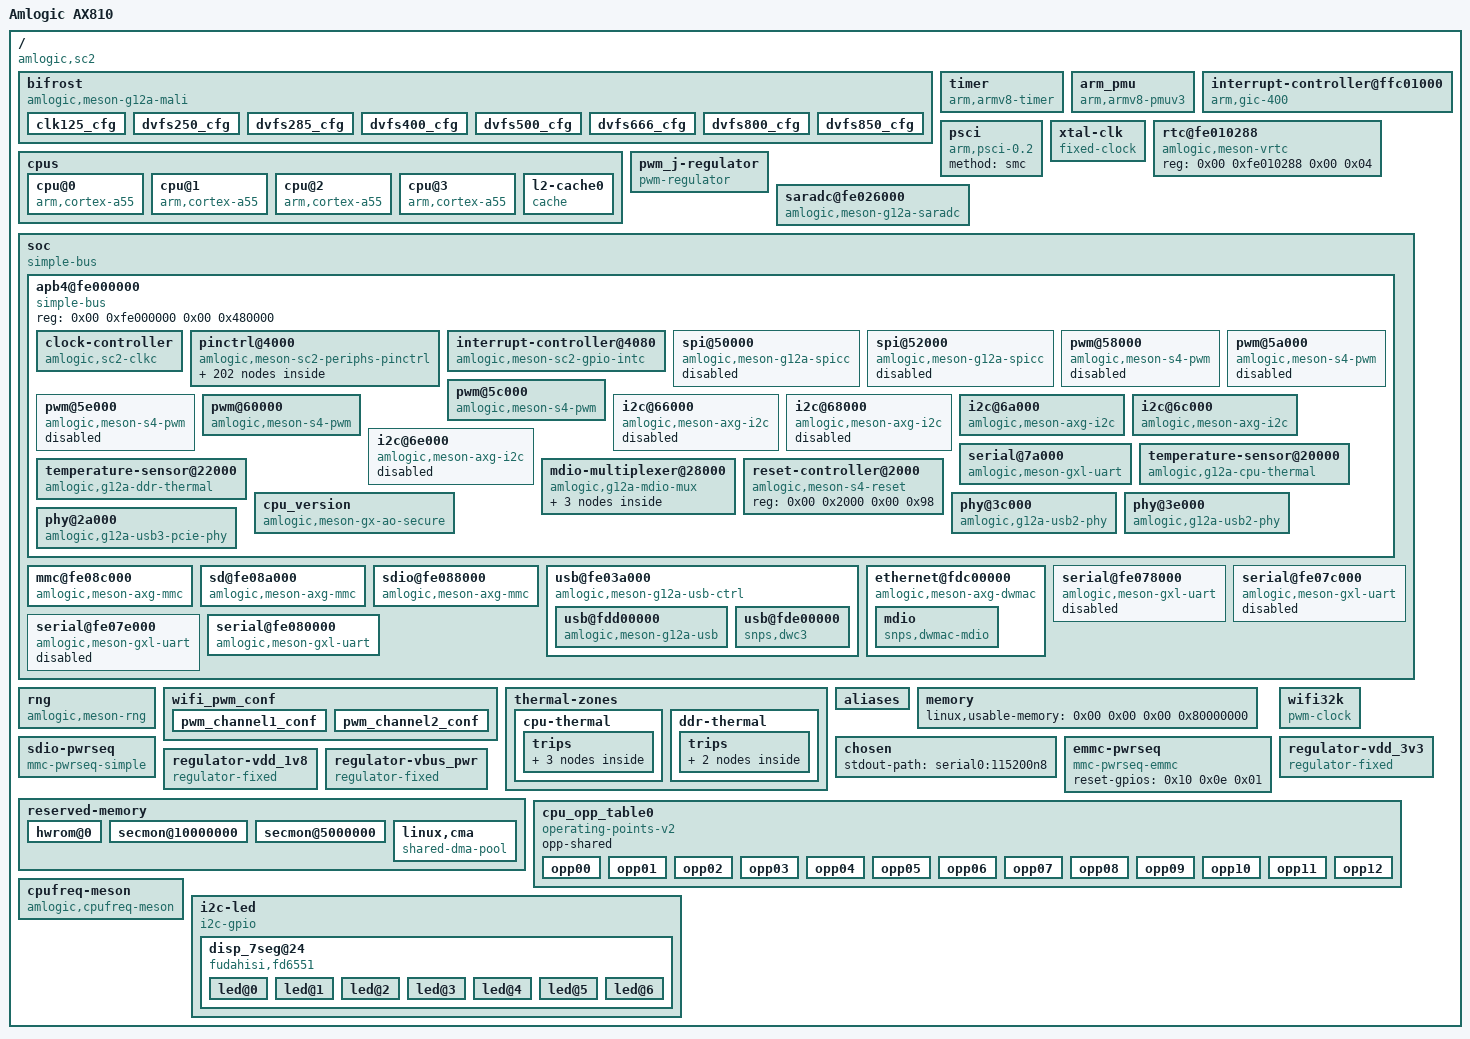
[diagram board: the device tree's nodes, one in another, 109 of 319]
/dts-v1/;
 
/ {
	model = "Amlogic AX810";
	compatible = "amlogic,sc2";
	interrupt-parent = <0x01>;
	#address-cells = <0x02>;
	#size-cells = <0x02>;
 
	bifrost {
		compatible = "amlogic,meson-g12a-mali";
		#cooling-cells = <0x02>;
		reg = <0x00 0xfe400000 0x00 0x4000 0x00 0xfe002000 0x00 0x1000 0x00 0xff800000 0x00 0x1000 0x00 0xff63c000 0x00 0x1000 0x00 0xfe002000 0x00 0x1000>;
		interrupt-parent = <0x01>;
		interrupts = <0x00 0x90 0x04 0x00 0x91 0x04 0x00 0x92 0x04>;
		interrupt-names = "gpu\0mmu\0job";
		tbl = <0x02 0x03 0x04 0x05 0x06 0x06>;
		resets = <0x07 0x22 0x07 0x21>;
		clk_cntl_reg = <0x57>;
		clocks = <0x08 0x93>;
		clock-names = "gpu_mux";
		assigned-clocks = <0x08 0x8d 0x08 0x8f 0x08 0x93>;
		assigned-clock-parents = <0x08 0x0f 0x00 0x08 0x8f>;
		assigned-clock-rates = <0x00 0x2faf0800 0x00>;
		phandle = <0x2d>;
 
		clk125_cfg {
			clk_freq = <0x7735940>;
			clk_parent = "fclk_div4";
			clkp_freq = <0x1dcd6500>;
			clk_reg = <0xa03>;
			voltage = <0x47e>;
			keep_count = <0x05>;
			threshold = <0x1e 0x78>;
			phandle = <0x2e>;
		};
 
		dvfs250_cfg {
			clk_freq = <0xee6b280>;
			clk_parent = "fclk_div4";
			clkp_freq = <0x1dcd6500>;
			clk_reg = <0xa01>;
			voltage = <0x47e>;
			keep_count = <0x05>;
			threshold = <0x00 0x4c>;
			phandle = <0x2f>;
		};
 
		dvfs285_cfg {
			clk_freq = <0x1107a76d>;
			clk_parent = "fclk_div7";
			clkp_freq = <0x1107a76d>;
			clk_reg = <0xe00>;
			voltage = <0x47e>;
			keep_count = <0x05>;
			threshold = <0x00 0x4c>;
			phandle = <0x02>;
		};
 
		dvfs400_cfg {
			clk_freq = <0x17d78400>;
			clk_parent = "fclk_div5";
			clkp_freq = <0x17d78400>;
			clk_reg = <0xc00>;
			voltage = <0x47e>;
			keep_count = <0x05>;
			threshold = <0x50 0x78>;
			phandle = <0x03>;
		};
 
		dvfs500_cfg {
			clk_freq = <0x1dcd6500>;
			clk_parent = "fclk_div4";
			clkp_freq = <0x1dcd6500>;
			clk_reg = <0xa00>;
			voltage = <0x47e>;
			keep_count = <0x05>;
			threshold = <0x50 0x78>;
			phandle = <0x04>;
		};
 
		dvfs666_cfg {
			clk_freq = <0x27bc86aa>;
			clk_parent = "fclk_div3";
			clkp_freq = <0x27bc86aa>;
			clk_reg = <0x800>;
			voltage = <0x47e>;
			keep_count = <0x05>;
			threshold = <0x50 0x78>;
			phandle = <0x05>;
		};
 
		dvfs800_cfg {
			clk_freq = <0x2faf0800>;
			clk_parent = "fclk_div2p5";
			clkp_freq = <0x2faf0800>;
			clk_reg = <0x600>;
			voltage = <0x47e>;
			keep_count = <0x05>;
			threshold = <0x50 0xff>;
			phandle = <0x30>;
		};
 
		dvfs850_cfg {
			clk_freq = <0x326cef80>;
			clk_parent = "gp0_pll";
			clkp_freq = <0x326cef80>;
			clk_reg = <0x200>;
			voltage = <0x47e>;
			keep_count = <0x05>;
			threshold = <0x50 0xff>;
			phandle = <0x06>;
		};
	};
 
	cpus {
		#address-cells = <0x02>;
		#size-cells = <0x00>;
		phandle = <0x31>;
 
		cpu@0 {
			device_type = "cpu";
			compatible = "arm,cortex-a55";
			reg = <0x00 0x00>;
			enable-method = "psci";
			next-level-cache = <0x09>;
			dynamic-power-coefficient = <0xe6>;
			#cooling-cells = <0x02>;
			clocks = <0x08 0x1b 0x08 0x1a 0x08 0x03 0x08 0x24 0x08 0x23>;
			clock-names = "core_clk\0low_freq_clk_parent\0high_freq_clk_parent\0dsu_clk\0dsu_pre_parent";
			operating-points-v2 = <0x0a>;
			cpu-supply = <0x0b>;
			voltage-tolerance = <0x00>;
			clock-latency = <0xc350>;
			phandle = <0x32>;
		};
 
		cpu@1 {
			device_type = "cpu";
			compatible = "arm,cortex-a55";
			reg = <0x00 0x01>;
			enable-method = "psci";
			next-level-cache = <0x09>;
			dynamic-power-coefficient = <0xe6>;
			#cooling-cells = <0x02>;
			clocks = <0x08 0x1b 0x08 0x1a 0x08 0x03 0x08 0x24 0x08 0x23>;
			clock-names = "core_clk\0low_freq_clk_parent\0high_freq_clk_parent\0dsu_clk\0dsu_pre_parent";
			operating-points-v2 = <0x0a>;
			cpu-supply = <0x0b>;
			voltage-tolerance = <0x00>;
			clock-latency = <0xc350>;
			phandle = <0x33>;
		};
 
		cpu@2 {
			device_type = "cpu";
			compatible = "arm,cortex-a55";
			reg = <0x00 0x02>;
			enable-method = "psci";
			next-level-cache = <0x09>;
			dynamic-power-coefficient = <0xe6>;
			#cooling-cells = <0x02>;
			clocks = <0x08 0x1b 0x08 0x1a 0x08 0x03 0x08 0x24 0x08 0x23>;
			clock-names = "core_clk\0low_freq_clk_parent\0high_freq_clk_parent\0dsu_clk\0dsu_pre_parent";
			operating-points-v2 = <0x0a>;
			cpu-supply = <0x0b>;
			voltage-tolerance = <0x00>;
			clock-latency = <0xc350>;
			phandle = <0x34>;
		};
 
		cpu@3 {
			device_type = "cpu";
			compatible = "arm,cortex-a55";
			reg = <0x00 0x03>;
			enable-method = "psci";
			next-level-cache = <0x09>;
			dynamic-power-coefficient = <0xe6>;
			#cooling-cells = <0x02>;
			clocks = <0x08 0x1b 0x08 0x1a 0x08 0x03 0x08 0x24 0x08 0x23>;
			clock-names = "core_clk\0low_freq_clk_parent\0high_freq_clk_parent\0dsu_clk\0dsu_pre_parent";
			operating-points-v2 = <0x0a>;
			cpu-supply = <0x0b>;
			voltage-tolerance = <0x00>;
			clock-latency = <0xc350>;
			phandle = <0x35>;
		};
 
		l2-cache0 {
			compatible = "cache";
			phandle = <0x09>;
		};
	};
 
	timer {
		compatible = "arm,armv8-timer";
		interrupts = <0x01 0x0d 0xff08 0x01 0x0e 0xff08 0x01 0x0b 0xff08 0x01 0x0a 0xff08>;
	};
 
	arm_pmu {
		compatible = "arm,armv8-pmuv3";
		private-interrupts;
		interrupts = <0x00 0xeb 0x04 0x00 0xec 0x04 0x00 0xed 0x04 0x00 0xee 0x04>;
		reg = <0x00 0xff634680 0x00 0x04>;
		cpumasks = <0x0f>;
		relax-timer-ns = <0x989680>;
		max-wait-cnt = <0x2710>;
	};
 
	interrupt-controller@ffc01000 {
		compatible = "arm,gic-400";
		#interrupt-cells = <0x03>;
		#address-cells = <0x00>;
		interrupt-controller;
		reg = <0x00 0xfff01000 0x00 0x1000 0x00 0xfff02000 0x00 0x2000 0x00 0xfff04000 0x00 0x2000 0x00 0xfff06000 0x00 0x2000>;
		interrupts = <0x01 0x09 0xff04>;
		phandle = <0x01>;
	};
 
	psci {
		compatible = "arm,psci-0.2";
		method = "smc";
	};
 
	xtal-clk {
		compatible = "fixed-clock";
		clock-frequency = <0x16e3600>;
		clock-output-names = "xtal";
		#clock-cells = <0x00>;
		phandle = <0x0d>;
	};
 
	rtc@fe010288 {
		compatible = "amlogic,meson-vrtc";
		reg = <0x00 0xfe010288 0x00 0x04>;
		status = "okay";
		phandle = <0x36>;
	};
 
	pwm_j-regulator {
		compatible = "pwm-regulator";
		pwms = <0x0c 0x01 0x5dc 0x00>;
		regulator-name = "vddcpu0";
		regulator-min-microvolt = <0xa8368>;
		regulator-max-microvolt = <0x1001a8>;
		regulator-always-on;
		max-duty-cycle = <0x5dc>;
		voltage-table = <0x1001a8 0x00 0xfda98 0x03 0xfb388 0x06 0xf8c78 0x09 0xf6568 0x0c 0xf3e58 0x0e 0xf1748 0x11 0xef038 0x14 0xec928 0x17 0xea218 0x1a 0xe7b08 0x1d 0xe53f8 0x1f 0xe2ce8 0x22 0xe05d8 0x25 0xddec8 0x28 0xdb7b8 0x2b 0xd90a8 0x2d 0xd6998 0x30 0xd4288 0x33 0xd1b78 0x36 0xcf468 0x38 0xccd58 0x3b 0xca648 0x3e 0xc7f38 0x41 0xc5828 0x44 0xc3118 0x46 0xc0a08 0x49 0xbe2f8 0x4c 0xbbbe8 0x4f 0xb94d8 0x51 0xb6dc8 0x54 0xb46b8 0x57 0xb1fa8 0x59 0xaf898 0x5c 0xad188 0x5f 0xaaa78 0x62 0xa8368 0x64>;
		status = "okay";
		phandle = <0x0b>;
	};
 
	saradc@fe026000 {
		compatible = "amlogic,meson-g12a-saradc\0amlogic,meson-saradc";
		status = "okay";
		#io-channel-cells = <0x01>;
		clocks = <0x0d 0x08 0x138 0x08 0x106 0x08 0x104>;
		clock-names = "clkin\0core\0adc_clk\0adc_sel";
		interrupts = <0x00 0xb5 0x01>;
		reg = <0x00 0xfe026000 0x00 0x48>;
		phandle = <0x37>;
	};
 
	soc {
		compatible = "simple-bus";
		#address-cells = <0x02>;
		#size-cells = <0x02>;
		ranges;
 
		apb4@fe000000 {
			compatible = "simple-bus";
			reg = <0x00 0xfe000000 0x00 0x480000>;
			#address-cells = <0x02>;
			#size-cells = <0x02>;
			ranges = <0x00 0x00 0x00 0xfe000000 0x00 0x480000>;
			phandle = <0x38>;
 
			clock-controller {
				compatible = "amlogic,sc2-clkc";
				#clock-cells = <0x01>;
				reg = <0x00 0x00 0x00 0x49c 0x00 0x8000 0x00 0x2e8 0x00 0xe140 0x00 0x24>;
				reg-names = "basic\0pll\0cpu_clk";
				clocks = <0x0d>;
				clock-names = "xtal";
				status = "okay";
				phandle = <0x08>;
			};
 
			pinctrl@4000 {
				compatible = "amlogic,meson-sc2-periphs-pinctrl";
				#address-cells = <0x02>;
				#size-cells = <0x02>;
				ranges;
				phandle = <0x0e>;
 
				bank@4000 {
					reg = <0x00 0x4000 0x00 0x4c 0x00 0x40c0 0x00 0x220>;
					reg-names = "mux\0gpio";
					gpio-controller;
					#gpio-cells = <0x02>;
					gpio-ranges = <0x0e 0x00 0x00 0x57>;
					phandle = <0x10>;
				};
 
				i2c0_pins1 {
					phandle = <0x39>;
 
					mux {
						groups = "i2c0_sda_c\0i2c0_scl_c";
						function = "i2c0";
						bias-disable;
					};
				};
 
				i2c0_pins2 {
					phandle = <0x3a>;
 
					mux {
						groups = "i2c0_sda_h\0i2c0_scl_h";
						function = "i2c0";
						bias-disable;
					};
				};
 
				i2c0_pins3 {
					phandle = <0x3b>;
 
					mux {
						groups = "i2c0_sda_z0\0i2c0_scl_z1";
						function = "i2c0";
						bias-disable;
					};
				};
 
				i2c0_pins4 {
					phandle = <0x3c>;
 
					mux {
						groups = "i2c0_sda_z7\0i2c0_scl_z8";
						function = "i2c0";
						bias-disable;
					};
				};
 
				i2c1_pins1 {
					phandle = <0x3d>;
 
					mux {
						groups = "i2c1_sda_z\0i2c1_scl_z";
						function = "i2c1";
						bias-disable;
					};
				};
 
				i2c1_pins2 {
					phandle = <0x3e>;
 
					mux {
						groups = "i2c1_sda_x\0i2c1_scl_x";
						function = "i2c1";
						bias-disable;
					};
				};
 
				i2c1_pins3 {
					phandle = <0x3f>;
 
					mux {
						groups = "i2c1_sda_h2\0i2c1_scl_h3";
						function = "i2c1";
						bias-disable;
					};
				};
 
				i2c1_pins4 {
					phandle = <0x40>;
 
					mux {
						groups = "i2c1_sda_h6\0i2c1_scl_h7";
						function = "i2c1";
						bias-disable;
					};
				};
 
				i2c2_pins1 {
					phandle = <0x41>;
 
					mux {
						groups = "i2c2_sda_x\0i2c2_scl_x";
						function = "i2c2";
						bias-disable;
					};
				};
 
				i2c2_pins2 {
					phandle = <0x42>;
 
					mux {
						groups = "i2c2_sda_z10\0i2c2_scl_z11";
						function = "i2c2";
						bias-disable;
					};
				};
 
				i2c2_pins3 {
					phandle = <0x13>;
 
					mux {
						groups = "i2c2_sda_z14\0i2c2_scl_z15";
						function = "i2c2";
						bias-disable;
					};
				};
 
				i2c3_pins1 {
					phandle = <0x43>;
 
					mux {
						groups = "i2c3_sda_h\0i2c3_scl_h";
						function = "i2c3";
						bias-disable;
					};
				};
 
				i2c3_pins2 {
					phandle = <0x14>;
 
					mux {
						groups = "i2c3_sda_a\0i2c3_scl_a";
						function = "i2c3";
						bias-disable;
					};
				};
 
				i2c4_pins1 {
					phandle = <0x44>;
 
					mux {
						groups = "i2c4_sda_d\0i2c4_scl_d";
						function = "i2c4";
						bias-disable;
					};
				};
 
				i2c4_pins2 {
					phandle = <0x45>;
 
					mux {
						groups = "i2c4_sda_e\0i2c4_scl_e";
						function = "i2c4";
						bias-disable;
					};
				};
 
				a_uart1 {
					phandle = <0x25>;
 
					mux {
						groups = "uart_a_tx_d2\0uart_a_rx_d3";
						function = "uart_a";
					};
				};
 
				a_uart2 {
					phandle = <0x46>;
 
					mux {
						groups = "uart_a_tx_d8\0uart_a_rx_d9";
						function = "uart_a";
					};
				};
 
				c_uart {
					phandle = <0x26>;
 
					mux {
						groups = "uart_c_tx\0uart_c_rx";
						bias-pull-up;
						output-high;
						function = "uart_c";
					};
				};
 
				d_uart1 {
					phandle = <0x27>;
 
					mux {
						groups = "uart_d_tx_x6\0uart_d_rx_x7";
						function = "uart_d";
					};
				};
 
				d_uart2 {
					phandle = <0x47>;
 
					mux {
						groups = "uart_d_tx_x10\0uart_d_rx_x11";
						function = "uart_d";
					};
				};
 
				e_uart {
					phandle = <0x28>;
 
					mux {
						groups = "uart_e_tx\0uart_e_rx\0uart_e_cts\0uart_e_rts";
						bias-pull-up;
						output-high;
						function = "uart_e";
					};
				};
 
				emmc {
					phandle = <0x16>;
 
					mux-0 {
						groups = "emmc_nand_d0\0emmc_nand_d1\0emmc_nand_d2\0emmc_nand_d3\0emmc_nand_d4\0emmc_nand_d5\0emmc_nand_d6\0emmc_nand_d7\0emmc_cmd";
						function = "emmc";
						bias-pull-up;
					};
 
					mux-1 {
						groups = "emmc_clk";
						function = "emmc";
						bias-disable;
					};
				};
 
				emmc-ds {
					phandle = <0x17>;
 
					mux {
						groups = "emmc_nand_dqs";
						function = "emmc";
						bias-pull-down;
					};
				};
 
				emmc_clk_gate {
					phandle = <0x18>;
 
					mux {
						groups = "GPIOB_8";
						function = "gpio_periphs";
						bias-pull-down;
					};
				};
 
				all_nand_pins {
					phandle = <0x48>;
 
					mux {
						groups = "emmc_nand_d0\0emmc_nand_d1\0emmc_nand_d2\0emmc_nand_d3\0emmc_nand_d4\0emmc_nand_d5\0emmc_nand_d6\0emmc_nand_d7\0nand_ce0\0nand_ale\0nand_cle\0nand_wen_clk\0nand_ren_wr";
						function = "nand";
						input-enable;
					};
				};
 
				nand_cs {
					phandle = <0x49>;
 
					mux {
						groups = "nand_ce0";
						function = "nand";
					};
				};
 
				sd_to_ao_uart_clr_pins {
					phandle = <0x4a>;
 
					mux {
						groups = "GPIOD_0\0GPIOD_1";
						function = "gpio_periphs";
					};
				};
 
				sdcard_pins {
					phandle = <0x1c>;
 
					mux-0 {
						groups = "sdcard_d0_c\0sdcard_d1_c\0sdcard_d2_c\0sdcard_d3_c\0sdcard_cmd_c";
						function = "sdcard";
						bias-pull-up;
					};
 
					mux-1 {
						groups = "sdcard_clk_c";
						function = "sdcard";
						bias-pull-up;
					};
				};
 
				sdio_clk_gate_pins {
					phandle = <0x1d>;
 
					mux {
						groups = "sdcard_clk_c";
						function = "sdcard";
						bias-pull-down;
					};
				};
 
				sdio {
					phandle = <0x1e>;
 
					mux-0 {
						groups = "sdio_d0_x\0sdio_d1_x\0sdio_d2_x\0sdio_d3_x\0sdio_cmd_x";
						function = "sdio";
						bias-pull-up;
					};
 
					mux-1 {
						groups = "sdio_clk_x";
						function = "sdio";
						bias-disable;
					};
				};
 
				sdio_clk_gate {
					phandle = <0x1f>;
 
					mux {
						groups = "GPIOX_4";
						function = "gpio_periphs";
						bias-pull-down;
					};
				};
 
				hdmitx_hpd {
					phandle = <0x4b>;
 
					mux {
						groups = "hdmitx_hpd_in";
						function = "hdmitx";
						bias-disable;
					};
				};
 
				hdmitx_hpd_gpio {
					phandle = <0x4c>;
 
					mux {
						groups = "GPIOH_1";
						function = "gpio_periphs";
						bias-disable;
					};
				};
 
				hdmitx_ddc {
					phandle = <0x4d>;
 
					mux {
						groups = "hdmitx_sda\0hdmitx_sck";
						function = "hdmitx";
						bias-disable;
					};
				};
 
				ee_ceca {
					phandle = <0x4e>;
 
					mux {
						groups = "cec_a_h";
						function = "cec_a";
					};
				};
 
				ee_cecb {
					phandle = <0x4f>;
 
					mux {
						groups = "cec_b_h";
						function = "cec_b";
					};
				};
 
				jtag_a_pin {
					phandle = <0x50>;
 
					mux {
						groups = "jtag_1_tdi\0jtag_1_tdo\0jtag_1_clk\0jtag_1_tms";
						function = "jtag_1";
					};
				};
 
				jtag_b_pin {
					phandle = <0x51>;
 
					mux {
						groups = "jtag_2_tdi\0jtag_2_tdo\0jtag_2_clk\0jtag_2_tms";
						function = "jtag_2";
					};
				};
 
				pwm_a_pins1 {
					phandle = <0x52>;
 
					mux {
						groups = "pwm_a_e";
						function = "pwm_a";
					};
				};
 
				pwm_a_pins2 {
					phandle = <0x53>;
 
					mux {
						groups = "pwm_a_x";
						function = "pwm_a";
					};
				};
 
				pwm_b_pins1 {
					phandle = <0x54>;
 
					mux {
						groups = "pwm_b_h";
						function = "pwm_b";
					};
				};
 
				pwm_b_pins2 {
					phandle = <0x55>;
 
					mux {
						groups = "pwm_b_z0";
						function = "pwm_b";
					};
				};
 
				pwm_b_pins3 {
					phandle = <0x56>;
 
					mux {
						groups = "pwm_b_z13";
						function = "pwm_b";
					};
				};
 
				pwm_b_pins4 {
					phandle = <0x57>;
 
					mux {
						groups = "pwm_b_x7";
						function = "pwm_b";
					};
				};
 
				pwm_b_pins5 {
					phandle = <0x58>;
 
					mux {
						groups = "pwm_b_x19";
						function = "pwm_b";
					};
				};
 
				pwm_c_pins1 {
					phandle = <0x59>;
 
					mux {
						groups = "pwm_c_c";
						function = "pwm_c";
					};
				};
 
				pwm_c_pins2 {
					phandle = <0x5a>;
 
					mux {
						groups = "pwm_c_x";
						function = "pwm_c";
					};
				};
 
				pwm_c_pins3 {
					phandle = <0x5b>;
 
					mux {
						groups = "pwm_c_z";
						function = "pwm_c";
					};
				};
 
				pwm_d_pins1 {
					phandle = <0x5c>;
 
					mux {
						groups = "pwm_d_z";
						function = "pwm_d";
					};
				};
 
				pwm_d_pins2 {
					phandle = <0x5d>;
 
					mux {
						groups = "pwm_d_x3";
						function = "pwm_d";
					};
				};
 
				pwm_d_pins3 {
					phandle = <0x5e>;
 
					mux {
						groups = "pwm_d_x6";
						function = "pwm_d";
					};
				};
 
				pwm_e_pins {
					phandle = <0x12>;
 
					mux {
						groups = "pwm_e";
						function = "pwm_e";
					};
				};
 
				pwm_f_pins1 {
					phandle = <0x5f>;
 
					mux {
						groups = "pwm_f_x";
						function = "pwm_f";
					};
				};
 
				pwm_f_pins2 {
					phandle = <0x60>;
 
					mux {
						groups = "pwm_f_h";
						function = "pwm_f";
					};
				};
 
				pwm_f_pins3 {
					phandle = <0x61>;
 
					mux {
						groups = "pwm_f_z";
						function = "pwm_f";
					};
				};
 
				pwm_g_pins {
					phandle = <0x62>;
 
					mux {
						groups = "pwm_g";
						function = "pwm_g";
					};
				};
 
				pwm_h_pins {
					phandle = <0x63>;
 
					mux {
						groups = "pwm_h";
						function = "pwm_h";
					};
				};
 
				pwm_i_pins1 {
					phandle = <0x64>;
 
					mux {
						groups = "pwm_i_d4";
						function = "pwm_i";
					};
				};
 
				pwm_i_pins2 {
					phandle = <0x65>;
 
					mux {
						groups = "pwm_i_d6";
						function = "pwm_i";
					};
				};
 
				pwm_j_pins1 {
					phandle = <0x66>;
 
					mux {
						groups = "pwm_j_e";
						function = "pwm_j";
					};
				};
 
				pwm_j_pins2 {
					phandle = <0x67>;
 
					mux {
						groups = "pwm_j_d5";
						function = "pwm_j";
					};
				};
 
				pwm_j_pins3 {
					phandle = <0x68>;
 
					mux {
						groups = "pwm_j_d10";
						function = "pwm_j";
					};
				};
 
				pwm_i_hiz_pins {
					phandle = <0x69>;
 
					mux {
						groups = "pwm_i_hiz";
						function = "pwm_i_hiz";
					};
				};
 
				pwm_g_hiz_pins {
					phandle = <0x6a>;
 
					mux {
						groups = "pwm_g_hiz";
						function = "pwm_g_hiz";
					};
				};
 
				remote_pin {
					phandle = <0x6b>;
 
					mux {
						groups = "remote_input_d5";
						function = "remote_input";
						bias-disable;
					};
				};
 
				spicc0_pins_x {
					phandle = <0x0f>;
 
					mux {
						groups = "spi_a_mosi_x\0spi_a_miso_x\0spi_a_sclk_x";
						function = "spi_a";
					};
				};
 
				spicc0_pins_c {
					phandle = <0x6c>;
 
					mux {
						groups = "spi_a_mosi_c\0spi_a_miso_c\0spi_a_sclk_c";
						function = "spi_a";
					};
				};
 
				spicc1_pins_h {
					phandle = <0x11>;
 
					mux {
						groups = "spi_b_mosi_h\0spi_b_miso_h\0spi_b_sclk_h";
						function = "spi_b";
					};
				};
 
				spifc_pins {
					phandle = <0x6d>;
 
					mux {
						groups = "nor_hold\0nor_d\0nor_q\0nor_c\0nor_wp\0nor_cs";
						function = "nor";
					};
				};
 
				irblaster_pin1 {
					phandle = <0x6e>;
 
					mux {
						groups = "remote_out_h";
						function = "remote_out";
					};
				};
 
				irblaster_pin2 {
					phandle = <0x6f>;
 
					mux {
						groups = "remote_out_z";
						function = "remote_out";
					};
				};
 
				irblaster_pin3 {
					phandle = <0x70>;
 
					mux {
						groups = "remote_out_d4";
						function = "remote_out";
					};
				};
 
				irblaster_pin4 {
					phandle = <0x71>;
 
					mux {
						groups = "remote_out_d9";
						function = "remote_out";
					};
				};
 
				sd_iso7816_pins {
					phandle = <0x72>;
 
					mux {
						groups = "iso7816_clk_c\0iso7816_data_c";
						function = "iso7816";
						input-enable;
						bias-pull-down;
					};
				};
 
				iso7816_pins_mode_0 {
					phandle = <0x73>;
 
					mux {
						groups = "iso7816_data_c";
						function = "iso7816";
						input-enable;
						bias-pull-down;
					};
				};
 
				iso7816_pins_mode_1 {
					phandle = <0x74>;
 
					mux {
						groups = "iso7816_data_x";
						function = "iso7816";
						input-enable;
						bias-pull-down;
					};
				};
 
				iso7816_pins_mode_2 {
					phandle = <0x75>;
 
					mux {
						groups = "iso7816_data_h";
						function = "iso7816";
						input-enable;
						bias-pull-down;
					};
				};
 
				iso7816_pin_data_m_0_h {
					phandle = <0x76>;
 
					mux {
						groups = "GPIOC_6";
						function = "gpio_periphs";
						output-high;
						bias-pull-up;
					};
				};
 
				iso7816_pin_data_m_1_h {
					phandle = <0x77>;
 
					mux {
						groups = "GPIOX_9";
						function = "gpio_periphs";
						output-high;
						bias-pull-up;
					};
				};
 
				iso7816_pin_data_m_2_h {
					phandle = <0x78>;
 
					mux {
						groups = "GPIOH_7";
						function = "gpio_periphs";
						output-high;
						bias-pull-up;
					};
				};
 
				iso7816_pin_data_m_0_l {
					phandle = <0x79>;
 
					mux {
						groups = "GPIOC_6";
						function = "gpio_periphs";
						output-low;
						bias-pull-up;
					};
				};
 
				iso7816_pin_data_m_1_l {
					phandle = <0x7a>;
 
					mux {
						groups = "GPIOX_9";
						function = "gpio_periphs";
						output-low;
						bias-pull-up;
					};
				};
 
				iso7816_pin_data_m_2_l {
					phandle = <0x7b>;
 
					mux {
						groups = "GPIOH_7";
						function = "gpio_periphs";
						output-low;
						bias-pull-up;
					};
				};
 
				tdm_a {
					phandle = <0x7c>;
 
					mux {
						groups = "tdm_sclk0\0tdm_fs0\0tdm_d3\0tdm_d4";
						function = "tdm";
					};
				};
 
				tdmin_a {
					phandle = <0x7d>;
 
					mux {
						groups = "tdma_din1";
						function = "tdma_in";
					};
				};
 
				tdmb_mclk {
					phandle = <0x7e>;
 
					mux {
						groups = "mclk0_a";
						function = "mclk0";
					};
				};
 
				tdmout_b {
					phandle = <0x7f>;
 
					mux {
						groups = "tdmb_sclk\0tdmb_fs\0tdmb_dout0";
						function = "tdmb_out";
					};
				};
 
				tdmin_b {
					phandle = <0x80>;
 
					mux {
						groups = "tdmb_din1";
						function = "tdmb_in";
					};
				};
 
				tdmc_mclk {
					phandle = <0x81>;
 
					mux {
						groups = "mclk1_a";
						function = "mclk1";
					};
				};
 
				tdmout_c {
					phandle = <0x82>;
 
					mux {
						groups = "tdmc_sclk_a\0tdmc_fs_a";
						function = "tdmc_out";
					};
				};
 
				tdmin_c {
					phandle = <0x83>;
 
					mux {
						groups = "tdmc_din0_a";
						function = "tdmc_in";
					};
				};
 
				spdifin {
					phandle = <0x84>;
 
					mux {
						groups = "spdif_in_h";
						function = "spdif_in";
					};
				};
 
				pdmin {
					phandle = <0x85>;
 
					mux {
						groups = "pdm_din0_c\0pdm_dclk_c";
						function = "pdm";
					};
				};
 
				spdifout {
					phandle = <0x86>;
 
					mux {
						groups = "spdif_out_d";
						function = "spdif_out";
					};
				};
 
				spdifout_a_mute {
					phandle = <0x87>;
 
					mux {
						groups = "GPIOD_10";
						function = "gpio_periphs";
						output-low;
					};
				};
 
				dvb_s_ts0_pins {
					phandle = <0x88>;
 
					tsin_a {
						groups = "tsin_a_sop_d\0tsin_a_valid_d\0tsin_a_clk_d\0tsin_a_din0_d";
						function = "tsin_a";
					};
				};
 
				dvb_s_ts1_pins {
					phandle = <0x89>;
 
					tsin_b {
						groups = "tsin_b_sop\0tsin_b_valid\0tsin_b_clk\0tsin_b_din0";
						function = "tsin_b";
					};
				};
 
				dvb_s_ts2_pins {
					phandle = <0x8a>;
 
					tsin_c {
						groups = "tsin_c_sop_z\0tsin_c_valid_z\0tsin_c_clk_z\0tsin_c_din0_z";
						function = "tsin_c";
					};
				};
 
				dvb_s_ts3_pins {
					phandle = <0x8b>;
 
					tsin_d {
						groups = "tsin_d_sop_z\0tsin_d_valid_z\0tsin_d_clk_z\0tsin_d_din0_z";
						function = "tsin_d";
					};
				};
			};
 
			interrupt-controller@4080 {
				compatible = "amlogic,meson-sc2-gpio-intc\0amlogic,meson-gpio-intc";
				reg = <0x00 0x4080 0x00 0x20>;
				interrupt-controller;
				#interrupt-cells = <0x02>;
				amlogic,channel-interrupts = <0x0a 0x0b 0x0c 0x0d 0x0e 0x0f 0x10 0x11 0x12 0x13 0x14 0x15>;
				phandle = <0x8c>;
			};
 
			spi@50000 {
				compatible = "amlogic,meson-g12a-spicc";
				reg = <0x00 0x50000 0x00 0x44>;
				interrupts = <0x00 0xb7 0x04>;
				clocks = <0x08 0x124 0x08 0xe2>;
				clock-names = "core\0async";
				#address-cells = <0x01>;
				#size-cells = <0x00>;
				status = "disabled";
				pinctrl-names = "default";
				pinctrl-0 = <0x0f>;
				cs-gpios = <0x10 0x3c 0x00>;
				phandle = <0x8d>;
			};
 
			spi@52000 {
				compatible = "amlogic,meson-g12a-spicc";
				reg = <0x00 0x52000 0x00 0x44>;
				interrupts = <0x00 0xb8 0x04>;
				clocks = <0x08 0x125 0x08 0xe5>;
				clock-names = "core\0async";
				#address-cells = <0x01>;
				#size-cells = <0x00>;
				status = "disabled";
				pinctrl-names = "default";
				pinctrl-0 = <0x11>;
				cs-gpios = <0x10 0x2f 0x00>;
				phandle = <0x8e>;
			};
 
			pwm@58000 {
				compatible = "amlogic,meson-s4-pwm";
				reg = <0x00 0x58000 0x00 0x24>;
				#pwm-cells = <0x03>;
				clocks = <0x08 0xe8 0x08 0xeb>;
				clock-names = "clkin0\0clkin1";
				status = "disabled";
				phandle = <0x8f>;
			};
 
			pwm@5a000 {
				compatible = "amlogic,meson-s4-pwm";
				reg = <0x00 0x5a000 0x00 0x24>;
				#pwm-cells = <0x03>;
				clocks = <0x08 0xee 0x08 0xf1>;
				clock-names = "clkin0\0clkin1";
				status = "disabled";
				phandle = <0x90>;
			};
 
			pwm@5c000 {
				compatible = "amlogic,meson-s4-pwm";
				reg = <0x00 0x5c000 0x00 0x24>;
				#pwm-cells = <0x03>;
				clocks = <0x08 0xf4 0x08 0xf7>;
				clock-names = "clkin0\0clkin1";
				status = "okay";
				pinctrl-0 = <0x12>;
				pinctrl-names = "default";
				phandle = <0x29>;
			};
 
			pwm@5e000 {
				compatible = "amlogic,meson-s4-pwm";
				reg = <0x00 0x5e000 0x00 0x24>;
				#pwm-cells = <0x03>;
				clocks = <0x08 0xfa 0x08 0xfd>;
				clock-names = "clkin0\0clkin1";
				status = "disabled";
				phandle = <0x91>;
			};
 
			pwm@60000 {
				compatible = "amlogic,meson-s4-pwm";
				reg = <0x00 0x60000 0x00 0x24>;
				#pwm-cells = <0x03>;
				clocks = <0x08 0x100 0x08 0x103>;
				clock-names = "clkin0\0clkin1";
				status = "okay";
				phandle = <0x0c>;
			};
 
			i2c@66000 {
				compatible = "amlogic,meson-axg-i2c";
				reg = <0x00 0x66000 0x00 0x48>;
				interrupts = <0x00 0xa0 0x01>;
				#address-cells = <0x01>;
				#size-cells = <0x00>;
				clocks = <0x08 0x129>;
				status = "disabled";
				phandle = <0x92>;
			};
 
			i2c@68000 {
				compatible = "amlogic,meson-axg-i2c";
				reg = <0x00 0x68000 0x00 0x48>;
				interrupts = <0x00 0xa1 0x01>;
				#address-cells = <0x01>;
				#size-cells = <0x00>;
				clocks = <0x08 0x12a>;
				status = "disabled";
				phandle = <0x93>;
			};
 
			i2c@6a000 {
				compatible = "amlogic,meson-axg-i2c";
				reg = <0x00 0x6a000 0x00 0x48>;
				interrupts = <0x00 0xa2 0x01>;
				#address-cells = <0x01>;
				#size-cells = <0x00>;
				clocks = <0x08 0x12b>;
				status = "okay";
				pinctrl-names = "default";
				pinctrl-0 = <0x13>;
				clock-frequency = <0x493e0>;
				phandle = <0x94>;
			};
 
			i2c@6c000 {
				compatible = "amlogic,meson-axg-i2c";
				reg = <0x00 0x6c000 0x00 0x48>;
				interrupts = <0x00 0xa3 0x01>;
				#address-cells = <0x01>;
				#size-cells = <0x00>;
				clocks = <0x08 0x12c>;
				status = "okay";
				pinctrl-names = "default";
				pinctrl-0 = <0x14>;
				clock-frequency = <0x493e0>;
				phandle = <0x95>;
			};
 
			i2c@6e000 {
				compatible = "amlogic,meson-axg-i2c";
				reg = <0x00 0x6e000 0x00 0x48>;
				interrupts = <0x00 0xa4 0x01>;
				#address-cells = <0x01>;
				#size-cells = <0x00>;
				clocks = <0x08 0x12d>;
				status = "disabled";
				phandle = <0x96>;
			};
 
			serial@7a000 {
				compatible = "amlogic,meson-gxl-uart\0amlogic,meson-ao-uart";
				reg = <0x00 0x7a000 0x00 0x18>;
				interrupts = <0x00 0xa9 0x01>;
				status = "okay";
				clocks = <0x0d 0x0d 0x0d>;
				clock-names = "xtal\0pclk\0baud";
				phandle = <0x97>;
			};
 
			temperature-sensor@20000 {
				compatible = "amlogic,g12a-cpu-thermal\0amlogic,g12a-thermal";
				reg = <0x00 0x20000 0x00 0x50 0x00 0x10328 0x00 0x04>;
				clocks = <0x08 0x8c>;
				#thermal-sensor-cells = <0x00>;
				phandle = <0x2a>;
			};
 
			temperature-sensor@22000 {
				compatible = "amlogic,g12a-ddr-thermal\0amlogic,g12a-thermal";
				reg = <0x00 0x22000 0x00 0x50 0x00 0x10370 0x00 0x04>;
				clocks = <0x08 0x8c>;
				#thermal-sensor-cells = <0x00>;
				phandle = <0x2b>;
			};
 
			mdio-multiplexer@28000 {
				compatible = "amlogic,g12a-mdio-mux";
				reg = <0x00 0x28000 0x00 0xa4>;
				clocks = <0x08 0x10c 0x0d 0x08 0x32>;
				clock-names = "pclk\0clkin0\0clkin1";
				mdio-parent-bus = <0x15>;
				#address-cells = <0x01>;
				#size-cells = <0x00>;
				phandle = <0x98>;
 
				mdio@0 {
					reg = <0x00>;
					#address-cells = <0x01>;
					#size-cells = <0x00>;
					phandle = <0x99>;
				};
 
				mdio@1 {
					reg = <0x01>;
					#address-cells = <0x01>;
					#size-cells = <0x00>;
					phandle = <0x9a>;
 
					ethernet_phy@8 {
						compatible = "ethernet-phy-id0180.3301\0ethernet-phy-ieee802.3-c22";
						interrupts = <0x00 0x4b 0x04>;
						reg = <0x08>;
						max-speed = <0x64>;
						phandle = <0x24>;
					};
				};
			};
 
			reset-controller@2000 {
				compatible = "amlogic,meson-s4-reset";
				reg = <0x00 0x2000 0x00 0x98>;
				#reset-cells = <0x01>;
				phandle = <0x07>;
			};
 
			cpu_version {
				compatible = "amlogic,meson-gx-ao-secure\0syscon";
				reg = <0x00 0x10220 0x00 0x140>;
				amlogic,has-chip-id;
			};
 
			phy@3c000 {
				compatible = "amlogic,g12a-usb2-phy";
				reg = <0x00 0x3c000 0x00 0x2000>;
				clocks = <0x0d>;
				clock-names = "xtal";
				resets = <0x07 0x08>;
				reset-names = "phy";
				#phy-cells = <0x00>;
				phandle = <0x21>;
			};
 
			phy@3e000 {
				compatible = "amlogic,g12a-usb2-phy";
				reg = <0x00 0x3e000 0x00 0x2000>;
				clocks = <0x0d>;
				clock-names = "xtal";
				resets = <0x07 0x09>;
				reset-names = "phy";
				#phy-cells = <0x00>;
				phandle = <0x22>;
			};
 
			phy@2a000 {
				compatible = "amlogic,g12a-usb3-pcie-phy";
				reg = <0x00 0x2a000 0x00 0x2000>;
				clocks = <0x08 0x2d>;
				clock-names = "ref_clk";
				resets = <0x07 0x2d>;
				reset-names = "phy";
				assigned-clocks = <0x08 0x2d>;
				assigned-clock-rates = <0x5f5e100>;
				#phy-cells = <0x01>;
				phandle = <0x23>;
			};
		};
 
		mmc@fe08c000 {
			compatible = "amlogic,meson-axg-mmc";
			reg = <0x00 0xfe08c000 0x00 0x800>;
			interrupts = <0x00 0xb2 0x01>;
			status = "okay";
			clocks = <0x08 0x113 0x08 0xd9 0x08 0x05>;
			clock-names = "core\0clkin0\0clkin1";
			pinctrl-0 = <0x16 0x17>;
			pinctrl-1 = <0x18>;
			pinctrl-names = "default\0clk-gate";
			bus-width = <0x08>;
			cap-mmc-highspeed;
			mmc-ddr-1_8v;
			mmc-hs200-1_8v;
			mmc-hs400-1_8v;
			max-frequency = <0xbebc200>;
			non-removable;
			disable-wp;
			mmc-pwrseq = <0x19>;
			vmmc-supply = <0x1a>;
			vqmmc-supply = <0x1b>;
			phandle = <0x9b>;
		};
 
		sd@fe08a000 {
			compatible = "amlogic,meson-axg-mmc";
			reg = <0x00 0xfe08a000 0x00 0x800>;
			interrupts = <0x00 0xb1 0x01>;
			status = "okay";
			clocks = <0x08 0x112 0x08 0xdf 0x08 0x05>;
			clock-names = "core\0clkin0\0clkin1";
			pinctrl-0 = <0x1c>;
			pinctrl-1 = <0x1d>;
			pinctrl-names = "sd_default\0clk-gate";
			bus-width = <0x04>;
			cap-sd-highspeed;
			max-frequency = <0xbebc200>;
			disable-wp;
			cd-gpios = <0x10 0x18 0x00>;
			cd-inverted;
			vmmc-supply = <0x1a>;
			vqmmc-supply = <0x1b>;
			phandle = <0x9c>;
		};
 
		sdio@fe088000 {
			compatible = "amlogic,meson-axg-mmc";
			reg = <0x00 0xfe088000 0x00 0x800>;
			interrupts = <0x00 0xb0 0x04>;
			status = "okay";
			clocks = <0x08 0x111 0x08 0xdc 0x08 0x05>;
			clock-names = "core\0clkin0\0clkin1";
			cap-sdio-irq;
			keep-power-in-suspend;
			pinctrl-0 = <0x1e>;
			pinctrl-1 = <0x1f>;
			pinctrl-names = "default\0clk-gate";
			#address-cells = <0x01>;
			#size-cells = <0x00>;
			bus-width = <0x04>;
			cap-sd-highspeed;
			sd-uhs-sdr50;
			sd-uhs-ddr50;
			sd-uhs-sdr104;
			max-frequency = <0xbebc200>;
			non-removable;
			disable-wp;
			mmc-pwrseq = <0x20>;
			vmmc-supply = <0x1a>;
			vqmmc-supply = <0x1b>;
			phandle = <0x9d>;
		};
 
		usb@fe03a000 {
			status = "okay";
			compatible = "amlogic,meson-g12a-usb-ctrl";
			reg = <0x00 0xfe03a000 0x00 0xa0>;
			interrupts = <0x00 0x10 0x04>;
			#address-cells = <0x02>;
			#size-cells = <0x02>;
			ranges;
			clocks = <0x08 0x127>;
			resets = <0x07 0x04>;
			dr_mode = "host";
			phys = <0x21 0x22 0x23 0x04>;
			phy-names = "usb2-phy0\0usb2-phy1\0usb3-phy0";
			phandle = <0x9e>;
 
			usb@fdd00000 {
				compatible = "amlogic,meson-g12a-usb\0snps,dwc2";
				reg = <0x00 0xfdd00000 0x00 0x100000>;
				interrupts = <0x00 0x83 0x04>;
				clocks = <0x08 0x131>;
				clock-names = "otg";
				phys = <0x22>;
				phy-names = "usb2-phy";
				dr_mode = "peripheral";
				g-rx-fifo-size = <0xc0>;
				g-np-tx-fifo-size = <0x80>;
				g-tx-fifo-size = <0x80 0x80 0x10 0x10 0x10>;
				phandle = <0x9f>;
			};
 
			usb@fde00000 {
				compatible = "snps,dwc3";
				reg = <0x00 0xfde00000 0x00 0x100000>;
				interrupts = <0x00 0x82 0x04>;
				dr_mode = "host";
				snps,dis_u2_susphy_quirk;
				snps,quirk-frame-length-adjustment = <0x20>;
				snps,parkmode-disable-ss-quirk;
				phandle = <0xa0>;
			};
		};
 
		ethernet@fdc00000 {
			compatible = "amlogic,meson-axg-dwmac\0snps,dwmac-3.70a\0snps,dwmac";
			reg = <0x00 0xfdc00000 0x00 0x10000 0x00 0xfe024000 0x00 0x08>;
			interrupts = <0x00 0x4a 0x04>;
			interrupt-names = "macirq";
			clocks = <0x08 0x11a 0x08 0x05 0x08 0x39>;
			clock-names = "stmmaceth\0clkin0\0clkin1";
			rx-fifo-depth = <0x1000>;
			tx-fifo-depth = <0x800>;
			mc_val = <0x4be0c>;
			status = "okay";
			phy-handle = <0x24>;
			phy-mode = "rmii";
			phandle = <0xa1>;
 
			mdio {
				#address-cells = <0x01>;
				#size-cells = <0x00>;
				compatible = "snps,dwmac-mdio";
				phandle = <0x15>;
			};
		};
 
		serial@fe078000 {
			compatible = "amlogic,meson-gxl-uart";
			reg = <0x00 0xfe078000 0x00 0x18>;
			interrupts = <0x00 0xa8 0x01>;
			status = "disabled";
			clocks = <0x0d 0x0d 0x0d>;
			clock-names = "xtal\0pclk\0baud";
			pinctrl-names = "default";
			pinctrl-0 = <0x25>;
			phandle = <0xa2>;
		};
 
		serial@fe07c000 {
			compatible = "amlogic,meson-gxl-uart";
			reg = <0x00 0xfe07c000 0x00 0x18>;
			interrupts = <0x00 0xaa 0x01>;
			status = "disabled";
			clocks = <0x0d 0x0d 0x0d>;
			clock-names = "xtal\0pclk\0baud";
			pinctrl-names = "default";
			pinctrl-0 = <0x26>;
			phandle = <0xa3>;
		};
 
		serial@fe07e000 {
			compatible = "amlogic,meson-gxl-uart";
			reg = <0x00 0xfe07e000 0x00 0x18>;
			interrupts = <0x00 0xab 0x01>;
			status = "disabled";
			clocks = <0x0d 0x0d 0x0d>;
			clock-names = "xtal\0pclk\0baud";
			pinctrl-names = "default";
			pinctrl-0 = <0x27>;
			phandle = <0xa4>;
		};
 
		serial@fe080000 {
			compatible = "amlogic,meson-gxl-uart";
			reg = <0x00 0xfe080000 0x00 0x18>;
			interrupts = <0x00 0xac 0x01>;
			status = "okay";
			clocks = <0x0d 0x0d 0x0d>;
			clock-names = "xtal\0pclk\0baud";
			pinctrl-names = "default";
			pinctrl-0 = <0x28>;
			uart-has-rtscts;
			phandle = <0xa5>;
		};
	};
 
	rng {
		compatible = "amlogic,meson-rng";
		status = "okay";
		#address-cells = <0x02>;
		#size-cells = <0x02>;
		reg = <0x00 0xfe440788 0x00 0x0c>;
		quality = [03 e8];
		version = <0x02>;
	};
 
	wifi_pwm_conf {
		phandle = <0xa6>;
 
		pwm_channel1_conf {
			pwms = <0x29 0x00 0x7756 0x00>;
			duty-cycle = <0x3ba6>;
			times = <0x08>;
		};
 
		pwm_channel2_conf {
			pwms = <0x29 0x02 0x7724 0x00>;
			duty-cycle = <0x3b92>;
			times = <0x0c>;
		};
	};
 
	thermal-zones {
 
		cpu-thermal {
			polling-delay = <0x3e8>;
			polling-delay-passive = <0x64>;
			thermal-sensors = <0x2a>;
			phandle = <0xa7>;
 
			trips {
 
				cpu-passive {
					temperature = <0x14c08>;
					hysteresis = <0x7d0>;
					type = "passive";
					phandle = <0xa8>;
				};
 
				cpu-hot {
					temperature = <0x17318>;
					hysteresis = <0x7d0>;
					type = "hot";
					phandle = <0xa9>;
				};
 
				cpu-critical {
					temperature = <0x1adb0>;
					hysteresis = <0x7d0>;
					type = "critical";
					phandle = <0xaa>;
				};
			};
		};
 
		ddr-thermal {
			polling-delay = <0x3e8>;
			polling-delay-passive = <0x64>;
			thermal-sensors = <0x2b>;
			phandle = <0xab>;
 
			trips {
 
				ddr-passive {
					temperature = <0x14c08>;
					hysteresis = <0x7d0>;
					type = "passive";
					phandle = <0xac>;
				};
 
				ddr-critical {
					temperature = <0x1adb0>;
					hysteresis = <0x7d0>;
					type = "critical";
					phandle = <0xad>;
				};
			};
		};
	};
 
	aliases {
		serial0 = "/soc/apb4@fe000000/serial@7a000";
		serial1 = "/soc/serial@fe080000";
		serial2 = "/soc/serial@fe07c000";
		serial3 = "/soc/serial@fe07e000";
		serial4 = "/soc/serial@fe078000";
		i2c0 = "/soc/apb4@fe000000/i2c@66000";
		i2c1 = "/soc/apb4@fe000000/i2c@68000";
		i2c2 = "/soc/apb4@fe000000/i2c@6a000";
		i2c3 = "/soc/apb4@fe000000/i2c@6c000";
		i2c4 = "/soc/apb4@fe000000/i2c@6e000";
		spi1 = "/soc/apb4@fe000000/spi@50000";
		spi2 = "/soc/apb4@fe000000/spi@52000";
	};
 
	memory {
		device_type = "memory";
		linux,usable-memory = <0x00 0x00 0x00 0x80000000>;
	};
 
	chosen {
		stdout-path = "serial0:115200n8";
	};
 
	emmc-pwrseq {
		compatible = "mmc-pwrseq-emmc";
		reset-gpios = <0x10 0x0e 0x01>;
		phandle = <0x19>;
	};
 
	wifi32k {
		compatible = "pwm-clock";
		#clock-cells = <0x00>;
		clock-frequency = <0x8000>;
		pwms = <0x29 0x00 0x7736 0x00>;
		phandle = <0x2c>;
	};
 
	sdio-pwrseq {
		compatible = "mmc-pwrseq-simple";
		reset-gpios = <0x10 0x38 0x01>;
		clocks = <0x2c>;
		clock-names = "ext_clock";
		phandle = <0x20>;
	};
 
	regulator-vdd_3v3 {
		compatible = "regulator-fixed";
		regulator-name = "VDD_3V3";
		regulator-min-microvolt = <0x325aa0>;
		regulator-max-microvolt = <0x325aa0>;
		phandle = <0x1a>;
	};
 
	regulator-vdd_1v8 {
		compatible = "regulator-fixed";
		regulator-name = "VDD_1V8";
		regulator-min-microvolt = <0x1b7740>;
		regulator-max-microvolt = <0x1b7740>;
		phandle = <0x1b>;
	};
 
	regulator-vbus_pwr {
		compatible = "regulator-fixed";
		regulator-name = "VBUS_PWR";
		regulator-min-microvolt = <0x4c4b40>;
		regulator-max-microvolt = <0x4c4b40>;
		gpio = <0x10 0x2f 0x00>;
		enable-active-high;
		phandle = <0xae>;
	};
 
	reserved-memory {
		#address-cells = <0x02>;
		#size-cells = <0x02>;
		ranges;
 
		hwrom@0 {
			reg = <0x00 0x00 0x00 0x1000000>;
			no-map;
			phandle = <0xaf>;
		};
 
		secmon@10000000 {
			reg = <0x00 0x10000000 0x00 0x200000>;
			no-map;
			phandle = <0xb0>;
		};
 
		secmon@5000000 {
			reg = <0x00 0x5000000 0x00 0x3400000>;
			no-map;
			phandle = <0xb1>;
		};
 
		linux,cma {
			compatible = "shared-dma-pool";
			reusable;
			size = <0x00 0xbc00000>;
			alignment = <0x00 0x400000>;
			linux,cma-default;
		};
	};
 
	cpu_opp_table0 {
		compatible = "operating-points-v2";
		status = "okay";
		opp-shared;
		phandle = <0x0a>;
 
		opp00 {
			opp-hz = <0x00 0x5f5e100>;
			opp-microvolt = <0xbe2f8>;
		};
 
		opp01 {
			opp-hz = <0x00 0xee6b280>;
			opp-microvolt = <0xbe2f8>;
		};
 
		opp02 {
			opp-hz = <0x00 0x1dcd6500>;
			opp-microvolt = <0xbe2f8>;
		};
 
		opp03 {
			opp-hz = <0x00 0x27c19cc0>;
			opp-microvolt = <0xc3118>;
		};
 
		opp04 {
			opp-hz = <0x00 0x3b9aca00>;
			opp-microvolt = <0xc3118>;
		};
 
		opp05 {
			opp-hz = <0x00 0x47868c00>;
			opp-microvolt = <0xc5828>;
		};
 
		opp06 {
			opp-hz = <0x00 0x53af5700>;
			opp-microvolt = <0xccd58>;
		};
 
		opp07 {
			opp-hz = <0x00 0x59682f00>;
			opp-microvolt = <0xcf468>;
		};
 
		opp08 {
			opp-hz = <0x00 0x5fd82200>;
			opp-microvolt = <0xd6998>;
		};
 
		opp09 {
			opp-hz = <0x00 0x6590fa00>;
			opp-microvolt = <0xe05d8>;
		};
 
		opp10 {
			opp-hz = <0x00 0x6b49d200>;
			opp-microvolt = <0xea218>;
		};
 
		opp11 {
			opp-hz = <0x00 0x71b9c500>;
			opp-microvolt = <0xf1748>;
		};
 
		opp12 {
			opp-hz = <0x00 0x77729d00>;
			opp-microvolt = <0xf8c78>;
		};
	};
 
	cpufreq-meson {
		compatible = "amlogic,cpufreq-meson";
		status = "okay";
	};
 
	i2c-led {
		compatible = "i2c-gpio";
		sda-gpios = <0x10 0x00 0x00>;
		i2c-gpio,sda-output-only;
		scl-gpios = <0x10 0x01 0x00>;
		i2c-gpio,scl-output-only;
		i2c-gpio,delay-us = <0x05>;
		#address-cells = <0x01>;
		#size-cells = <0x00>;
 
		disp_7seg@24 {
			compatible = "fudahisi,fd6551";
			reg = <0x24 0x37 0x36 0x35 0x34 0x33>;
			reg-names = "cmd\0grid_0\0grid_1\0grid_2\0grid_3\0symbols";
			#address-cells = <0x01>;
			#size-cells = <0x00>;
			fudahisi,segment-mapping = [00 01 02 03 04 05 06];
 
			led@0 {
				reg = <0x00>;
				function = "alarm";
			};
 
			led@1 {
				reg = <0x01>;
				function = "usb";
			};
 
			led@2 {
				reg = <0x02>;
				function = "pause";
			};
 
			led@3 {
				reg = <0x03>;
				function = "play";
			};
 
			led@4 {
				reg = <0x04>;
				function = "colon";
			};
 
			led@5 {
				reg = <0x05>;
				function = "lan";
			};
 
			led@6 {
				reg = <0x06>;
				function = "wlan";
			};
		};
	};
 
	__symbols__ {
		gpu = "/bifrost";
		dvfs125_cfg = "/bifrost/clk125_cfg";
		dvfs250_cfg = "/bifrost/dvfs250_cfg";
		dvfs285_cfg = "/bifrost/dvfs285_cfg";
		dvfs400_cfg = "/bifrost/dvfs400_cfg";
		dvfs500_cfg = "/bifrost/dvfs500_cfg";
		dvfs666_cfg = "/bifrost/dvfs666_cfg";
		dvfs800_cfg = "/bifrost/dvfs800_cfg";
		dvfs850_cfg = "/bifrost/dvfs850_cfg";
		cpus = "/cpus";
		CPU0 = "/cpus/cpu@0";
		CPU1 = "/cpus/cpu@1";
		CPU2 = "/cpus/cpu@2";
		CPU3 = "/cpus/cpu@3";
		l2 = "/cpus/l2-cache0";
		gic = "/interrupt-controller@ffc01000";
		xtal = "/xtal-clk";
		vrtc = "/rtc@fe010288";
		vddcpu0 = "/pwm_j-regulator";
		saradc = "/saradc@fe026000";
		apb4 = "/soc/apb4@fe000000";
		clkc = "/soc/apb4@fe000000/clock-controller";
		periphs_pinctrl = "/soc/apb4@fe000000/pinctrl@4000";
		gpio = "/soc/apb4@fe000000/pinctrl@4000/bank@4000";
		i2c0_pins1 = "/soc/apb4@fe000000/pinctrl@4000/i2c0_pins1";
		i2c0_pins2 = "/soc/apb4@fe000000/pinctrl@4000/i2c0_pins2";
		i2c0_pins3 = "/soc/apb4@fe000000/pinctrl@4000/i2c0_pins3";
		i2c0_pins4 = "/soc/apb4@fe000000/pinctrl@4000/i2c0_pins4";
		i2c1_pins1 = "/soc/apb4@fe000000/pinctrl@4000/i2c1_pins1";
		i2c1_pins2 = "/soc/apb4@fe000000/pinctrl@4000/i2c1_pins2";
		i2c1_pins3 = "/soc/apb4@fe000000/pinctrl@4000/i2c1_pins3";
		i2c1_pins4 = "/soc/apb4@fe000000/pinctrl@4000/i2c1_pins4";
		i2c2_pins1 = "/soc/apb4@fe000000/pinctrl@4000/i2c2_pins1";
		i2c2_pins2 = "/soc/apb4@fe000000/pinctrl@4000/i2c2_pins2";
		i2c2_pins3 = "/soc/apb4@fe000000/pinctrl@4000/i2c2_pins3";
		i2c3_pins1 = "/soc/apb4@fe000000/pinctrl@4000/i2c3_pins1";
		i2c3_pins2 = "/soc/apb4@fe000000/pinctrl@4000/i2c3_pins2";
		i2c4_pins1 = "/soc/apb4@fe000000/pinctrl@4000/i2c4_pins1";
		i2c4_pins2 = "/soc/apb4@fe000000/pinctrl@4000/i2c4_pins2";
		a_uart_pins1 = "/soc/apb4@fe000000/pinctrl@4000/a_uart1";
		a_uart_pins2 = "/soc/apb4@fe000000/pinctrl@4000/a_uart2";
		c_uart_pins = "/soc/apb4@fe000000/pinctrl@4000/c_uart";
		d_uart_pins1 = "/soc/apb4@fe000000/pinctrl@4000/d_uart1";
		d_uart_pins2 = "/soc/apb4@fe000000/pinctrl@4000/d_uart2";
		e_uart_pins = "/soc/apb4@fe000000/pinctrl@4000/e_uart";
		emmc_pins = "/soc/apb4@fe000000/pinctrl@4000/emmc";
		emmc_ds_pins = "/soc/apb4@fe000000/pinctrl@4000/emmc-ds";
		emmc_clk_gate_pins = "/soc/apb4@fe000000/pinctrl@4000/emmc_clk_gate";
		all_nand_pins = "/soc/apb4@fe000000/pinctrl@4000/all_nand_pins";
		nand_cs_pins = "/soc/apb4@fe000000/pinctrl@4000/nand_cs";
		sd_to_ao_uart_clr_pins = "/soc/apb4@fe000000/pinctrl@4000/sd_to_ao_uart_clr_pins";
		sdcard_pins = "/soc/apb4@fe000000/pinctrl@4000/sdcard_pins";
		sdcard_clk_gate_pins = "/soc/apb4@fe000000/pinctrl@4000/sdio_clk_gate_pins";
		sdio_pins = "/soc/apb4@fe000000/pinctrl@4000/sdio";
		sdio_clk_gate_pins = "/soc/apb4@fe000000/pinctrl@4000/sdio_clk_gate";
		hdmitx_hpd = "/soc/apb4@fe000000/pinctrl@4000/hdmitx_hpd";
		hdmitx_hpd_gpio = "/soc/apb4@fe000000/pinctrl@4000/hdmitx_hpd_gpio";
		hdmitx_ddc = "/soc/apb4@fe000000/pinctrl@4000/hdmitx_ddc";
		eecec_a = "/soc/apb4@fe000000/pinctrl@4000/ee_ceca";
		eecec_b = "/soc/apb4@fe000000/pinctrl@4000/ee_cecb";
		jtag_a_pins = "/soc/apb4@fe000000/pinctrl@4000/jtag_a_pin";
		jtag_b_pins = "/soc/apb4@fe000000/pinctrl@4000/jtag_b_pin";
		pwm_a_pins1 = "/soc/apb4@fe000000/pinctrl@4000/pwm_a_pins1";
		pwm_a_pins2 = "/soc/apb4@fe000000/pinctrl@4000/pwm_a_pins2";
		pwm_b_pins1 = "/soc/apb4@fe000000/pinctrl@4000/pwm_b_pins1";
		pwm_b_pins2 = "/soc/apb4@fe000000/pinctrl@4000/pwm_b_pins2";
		pwm_b_pins3 = "/soc/apb4@fe000000/pinctrl@4000/pwm_b_pins3";
		pwm_b_pins4 = "/soc/apb4@fe000000/pinctrl@4000/pwm_b_pins4";
		pwm_b_pins5 = "/soc/apb4@fe000000/pinctrl@4000/pwm_b_pins5";
		pwm_c_pins1 = "/soc/apb4@fe000000/pinctrl@4000/pwm_c_pins1";
		pwm_c_pins2 = "/soc/apb4@fe000000/pinctrl@4000/pwm_c_pins2";
		pwm_c_pins3 = "/soc/apb4@fe000000/pinctrl@4000/pwm_c_pins3";
		pwm_d_pins1 = "/soc/apb4@fe000000/pinctrl@4000/pwm_d_pins1";
		pwm_d_pins2 = "/soc/apb4@fe000000/pinctrl@4000/pwm_d_pins2";
		pwm_d_pins3 = "/soc/apb4@fe000000/pinctrl@4000/pwm_d_pins3";
		pwm_e_pins = "/soc/apb4@fe000000/pinctrl@4000/pwm_e_pins";
		pwm_f_pins1 = "/soc/apb4@fe000000/pinctrl@4000/pwm_f_pins1";
		pwm_f_pins2 = "/soc/apb4@fe000000/pinctrl@4000/pwm_f_pins2";
		pwm_f_pins3 = "/soc/apb4@fe000000/pinctrl@4000/pwm_f_pins3";
		pwm_g_pins = "/soc/apb4@fe000000/pinctrl@4000/pwm_g_pins";
		pwm_h_pins = "/soc/apb4@fe000000/pinctrl@4000/pwm_h_pins";
		pwm_i_pins1 = "/soc/apb4@fe000000/pinctrl@4000/pwm_i_pins1";
		pwm_i_pins2 = "/soc/apb4@fe000000/pinctrl@4000/pwm_i_pins2";
		pwm_j_pins1 = "/soc/apb4@fe000000/pinctrl@4000/pwm_j_pins1";
		pwm_j_pins2 = "/soc/apb4@fe000000/pinctrl@4000/pwm_j_pins2";
		pwm_j_pins3 = "/soc/apb4@fe000000/pinctrl@4000/pwm_j_pins3";
		pwm_i_hiz_pins = "/soc/apb4@fe000000/pinctrl@4000/pwm_i_hiz_pins";
		pwm_g_hiz_pins = "/soc/apb4@fe000000/pinctrl@4000/pwm_g_hiz_pins";
		remote_pins = "/soc/apb4@fe000000/pinctrl@4000/remote_pin";
		spicc0_pins_x = "/soc/apb4@fe000000/pinctrl@4000/spicc0_pins_x";
		spicc0_pins_c = "/soc/apb4@fe000000/pinctrl@4000/spicc0_pins_c";
		spicc1_pins_h = "/soc/apb4@fe000000/pinctrl@4000/spicc1_pins_h";
		spifc_pins = "/soc/apb4@fe000000/pinctrl@4000/spifc_pins";
		irblaster_pins1 = "/soc/apb4@fe000000/pinctrl@4000/irblaster_pin1";
		irblaster_pins2 = "/soc/apb4@fe000000/pinctrl@4000/irblaster_pin2";
		irblaster_pins3 = "/soc/apb4@fe000000/pinctrl@4000/irblaster_pin3";
		irblaster_pins4 = "/soc/apb4@fe000000/pinctrl@4000/irblaster_pin4";
		sd_iso7816_pins = "/soc/apb4@fe000000/pinctrl@4000/sd_iso7816_pins";
		iso7816_pins_mode_0 = "/soc/apb4@fe000000/pinctrl@4000/iso7816_pins_mode_0";
		iso7816_pins_mode_1 = "/soc/apb4@fe000000/pinctrl@4000/iso7816_pins_mode_1";
		iso7816_pins_mode_2 = "/soc/apb4@fe000000/pinctrl@4000/iso7816_pins_mode_2";
		iso7816_pin_data_m_0_h = "/soc/apb4@fe000000/pinctrl@4000/iso7816_pin_data_m_0_h";
		iso7816_pin_data_m_1_h = "/soc/apb4@fe000000/pinctrl@4000/iso7816_pin_data_m_1_h";
		iso7816_pin_data_m_2_h = "/soc/apb4@fe000000/pinctrl@4000/iso7816_pin_data_m_2_h";
		iso7816_pin_data_m_0_l = "/soc/apb4@fe000000/pinctrl@4000/iso7816_pin_data_m_0_l";
		iso7816_pin_data_m_1_l = "/soc/apb4@fe000000/pinctrl@4000/iso7816_pin_data_m_1_l";
		iso7816_pin_data_m_2_l = "/soc/apb4@fe000000/pinctrl@4000/iso7816_pin_data_m_2_l";
		tdm_a = "/soc/apb4@fe000000/pinctrl@4000/tdm_a";
		tdmin_a = "/soc/apb4@fe000000/pinctrl@4000/tdmin_a";
		tdmb_mclk = "/soc/apb4@fe000000/pinctrl@4000/tdmb_mclk";
		tdmout_b = "/soc/apb4@fe000000/pinctrl@4000/tdmout_b";
		tdmin_b = "/soc/apb4@fe000000/pinctrl@4000/tdmin_b";
		tdmc_mclk = "/soc/apb4@fe000000/pinctrl@4000/tdmc_mclk";
		tdmout_c = "/soc/apb4@fe000000/pinctrl@4000/tdmout_c";
		tdmin_c = "/soc/apb4@fe000000/pinctrl@4000/tdmin_c";
		spdifin = "/soc/apb4@fe000000/pinctrl@4000/spdifin";
		pdmin = "/soc/apb4@fe000000/pinctrl@4000/pdmin";
		spdifout = "/soc/apb4@fe000000/pinctrl@4000/spdifout";
		spdifout_a_mute = "/soc/apb4@fe000000/pinctrl@4000/spdifout_a_mute";
		dvb_s_ts0_pins = "/soc/apb4@fe000000/pinctrl@4000/dvb_s_ts0_pins";
		dvb_s_ts1_pins = "/soc/apb4@fe000000/pinctrl@4000/dvb_s_ts1_pins";
		dvb_s_ts2_pins = "/soc/apb4@fe000000/pinctrl@4000/dvb_s_ts2_pins";
		dvb_s_ts3_pins = "/soc/apb4@fe000000/pinctrl@4000/dvb_s_ts3_pins";
		gpio_intc = "/soc/apb4@fe000000/interrupt-controller@4080";
		spicc0 = "/soc/apb4@fe000000/spi@50000";
		spicc1 = "/soc/apb4@fe000000/spi@52000";
		pwm_ab = "/soc/apb4@fe000000/pwm@58000";
		pwm_cd = "/soc/apb4@fe000000/pwm@5a000";
		pwm_ef = "/soc/apb4@fe000000/pwm@5c000";
		pwm_gh = "/soc/apb4@fe000000/pwm@5e000";
		pwm_ij = "/soc/apb4@fe000000/pwm@60000";
		i2c0 = "/soc/apb4@fe000000/i2c@66000";
		i2c1 = "/soc/apb4@fe000000/i2c@68000";
		i2c2 = "/soc/apb4@fe000000/i2c@6a000";
		i2c3 = "/soc/apb4@fe000000/i2c@6c000";
		i2c4 = "/soc/apb4@fe000000/i2c@6e000";
		uart_B = "/soc/apb4@fe000000/serial@7a000";
		cpu_temp = "/soc/apb4@fe000000/temperature-sensor@20000";
		ddr_temp = "/soc/apb4@fe000000/temperature-sensor@22000";
		eth_phy = "/soc/apb4@fe000000/mdio-multiplexer@28000";
		ext_mdio = "/soc/apb4@fe000000/mdio-multiplexer@28000/mdio@0";
		int_mdio = "/soc/apb4@fe000000/mdio-multiplexer@28000/mdio@1";
		internal_ephy = "/soc/apb4@fe000000/mdio-multiplexer@28000/mdio@1/ethernet_phy@8";
		reset = "/soc/apb4@fe000000/reset-controller@2000";
		usb2_phy0 = "/soc/apb4@fe000000/phy@3c000";
		usb2_phy1 = "/soc/apb4@fe000000/phy@3e000";
		usb3_pcie_phy = "/soc/apb4@fe000000/phy@2a000";
		sd_emmc_c = "/soc/mmc@fe08c000";
		sd_emmc_b = "/soc/sd@fe08a000";
		sd_emmc_a = "/soc/sdio@fe088000";
		usb = "/soc/usb@fe03a000";
		dwc2 = "/soc/usb@fe03a000/usb@fdd00000";
		dwc3 = "/soc/usb@fe03a000/usb@fde00000";
		ethmac = "/soc/ethernet@fdc00000";
		mdio0 = "/soc/ethernet@fdc00000/mdio";
		uart_A = "/soc/serial@fe078000";
		uart_C = "/soc/serial@fe07c000";
		uart_D = "/soc/serial@fe07e000";
		uart_E = "/soc/serial@fe080000";
		wifi_pwm_conf = "/wifi_pwm_conf";
		cpu_thermal = "/thermal-zones/cpu-thermal";
		cpu_passive = "/thermal-zones/cpu-thermal/trips/cpu-passive";
		cpu_hot = "/thermal-zones/cpu-thermal/trips/cpu-hot";
		cpu_critical = "/thermal-zones/cpu-thermal/trips/cpu-critical";
		ddr_thermal = "/thermal-zones/ddr-thermal";
		ddr_passive = "/thermal-zones/ddr-thermal/trips/ddr-passive";
		ddr_critical = "/thermal-zones/ddr-thermal/trips/ddr-critical";
		emmc_pwrseq = "/emmc-pwrseq";
		wifi32k = "/wifi32k";
		sdio_pwrseq = "/sdio-pwrseq";
		vdd_3v3 = "/regulator-vdd_3v3";
		vdd_1v8 = "/regulator-vdd_1v8";
		vbus_pwr = "/regulator-vbus_pwr";
		hwrom_reserved = "/reserved-memory/hwrom@0";
		secmon_reserved1 = "/reserved-memory/secmon@10000000";
		secmon_reserved2 = "/reserved-memory/secmon@5000000";
		cpu_opp_table0 = "/cpu_opp_table0";
	};
};
